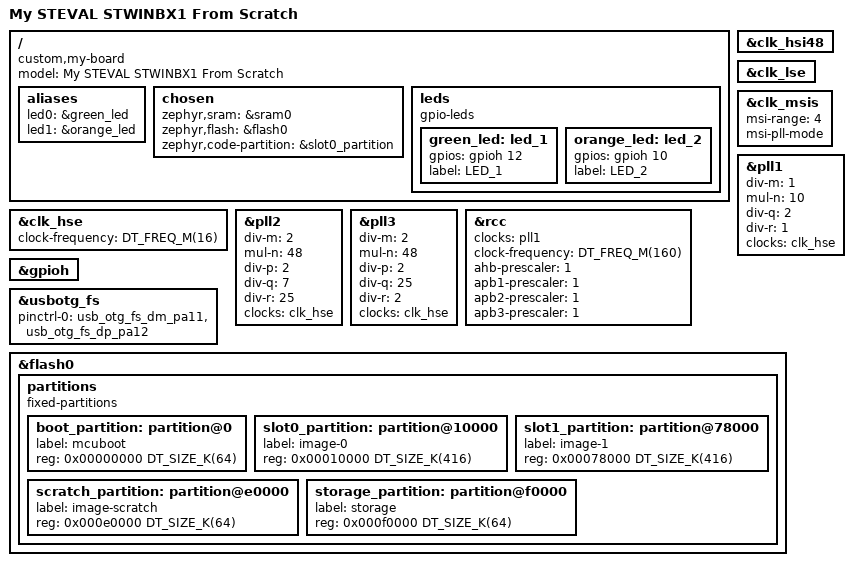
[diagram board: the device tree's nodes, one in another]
/dts-v1/;

#include <st/u5/stm32u585Xi.dtsi>
#include <st/u5/stm32u585aiixq-pinctrl.dtsi>

/ {
	model = "My STEVAL STWINBX1 From Scratch";
	compatible = "custom,my-board";

	aliases {
		led0 = &green_led;
		led1 = &orange_led;
	};

	chosen {
		zephyr,sram = &sram0;
		zephyr,flash = &flash0;
		zephyr,code-partition = &slot0_partition;
	};

	leds {
		compatible = "gpio-leds";

		green_led: led_1 {
			gpios = <&gpioh 12 GPIO_ACTIVE_HIGH>;
			label = "LED_1";
		};

		orange_led: led_2 {
			gpios = <&gpioh 10 GPIO_ACTIVE_HIGH>;
			label = "LED_2";
		};
	};


};

&clk_hsi48 {
	status = "okay";
};

&clk_hse {
	clock-frequency = <DT_FREQ_M(16)>;
	status = "okay";
};

&clk_lse {
	status = "okay";
};

&clk_msis {
	status = "okay";
	msi-range = <4>;
	msi-pll-mode;
};

&pll1 {
	div-m = <1>;
	mul-n = <10>;
	div-q = <2>;
	div-r = <1>;
	clocks = <&clk_hse>;
	status = "okay";
};

&pll2 {
	div-m = <2>;
	mul-n = <48>;
	div-p = <2>;
	div-q = <7>;
	div-r = <25>;
	clocks = <&clk_hse>;
	status = "okay";
};

&pll3 {
	div-m = <2>;
	mul-n = <48>;
	div-p = <2>;
	div-q = <25>;
	div-r = <2>;
	clocks = <&clk_hse>;
	status = "okay";
};

&rcc {
	clocks = <&pll1>;
	clock-frequency = <DT_FREQ_M(160)>;
	ahb-prescaler = <1>;
	apb1-prescaler = <1>;
	apb2-prescaler = <1>;
	apb3-prescaler = <1>;
};

&gpioh {
    status = "okay";
};

zephyr_udc0: &usbotg_fs {
	pinctrl-0 = <&usb_otg_fs_dm_pa11 &usb_otg_fs_dp_pa12>;
	pinctrl-names = "default";
	status = "okay";
};

#include <../boards/common/usb/cdc_acm_serial.dtsi>

&flash0 {
	partitions {
		compatible = "fixed-partitions";
		#address-cells = <1>;
		#size-cells = <1>;

		/*
		 * Following flash partition is dedicated to the use of steval_stwinbx1
		 * with TZEN=0 (so w/o TFM).
		 * Set the partitions with first MB to make use of the whole Bank1
		 */
		boot_partition: partition@0 {
			label = "mcuboot";
			reg = <0x00000000 DT_SIZE_K(64)>;
		};

		slot0_partition: partition@10000 {
			label = "image-0";
			reg = <0x00010000 DT_SIZE_K(416)>;
		};

		slot1_partition: partition@78000 {
			label = "image-1";
			reg = <0x00078000 DT_SIZE_K(416)>;
		};

		scratch_partition: partition@e0000 {
			label = "image-scratch";
			reg = <0x000e0000 DT_SIZE_K(64)>;
		};

		storage_partition: partition@f0000 {
			label = "storage";
			reg = <0x000f0000 DT_SIZE_K(64)>;
		};
	};
};
